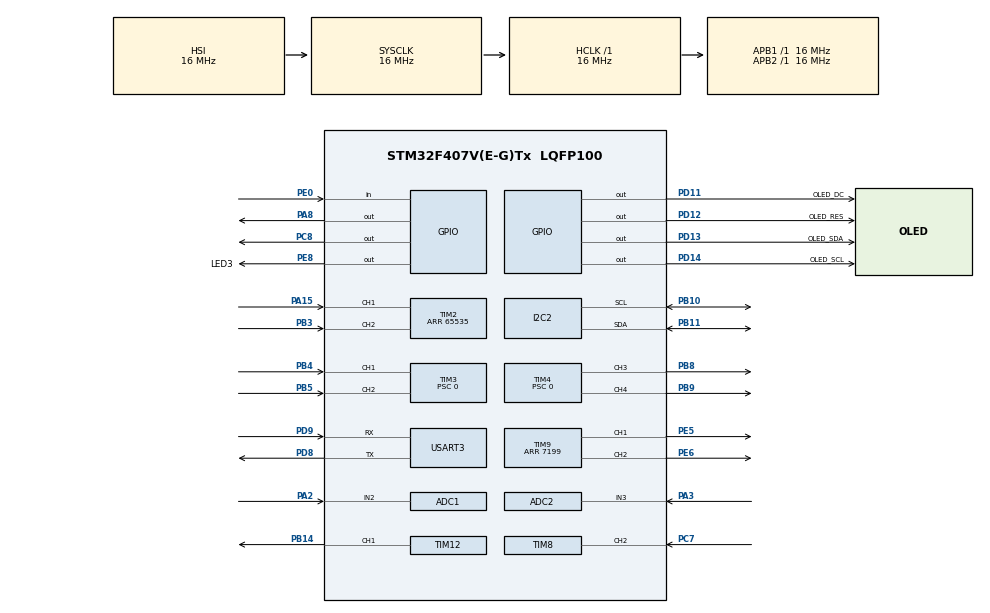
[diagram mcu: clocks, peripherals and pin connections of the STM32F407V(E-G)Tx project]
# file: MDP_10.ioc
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ADC1.Channel-1\#ChannelRegularConversion=ADC_CHANNEL_2
ADC1.NbrOfConversionFlag=1
ADC1.Rank-1\#ChannelRegularConversion=1
ADC1.SamplingTime-1\#ChannelRegularConversion=ADC_SAMPLETIME_3CYCLES
ADC1.master=1
ADC2.Channel-0\#ChannelRegularConversion=ADC_CHANNEL_3
ADC2.NbrOfConversionFlag=1
ADC2.Rank-0\#ChannelRegularConversion=1
ADC2.SamplingTime-0\#ChannelRegularConversion=ADC_SAMPLETIME_3CYCLES
FREERTOS.Tasks01=defaultTask,8,128,StartDefaultTask,Default,NULL,Dynamic,NULL,NULL;ShowTask,8,128,show,Default,NULL,Dynamic,NULL,NULL;MotorTask,8,128,motors,Default,NULL,Dynamic,NULL,NULL;EncoderTask,8,256,encoder,Default,NULL,Dynamic,NULL,NULL;ServoTask,8,128,servo,Default,NULL,Dynamic,NULL,NULL;EncoderBTask,8,256,encoder_B,Default,NULL,Dynamic,NULL,NULL;UltrasonicSenso,8,128,ultra_sensor,Default,NULL,Dynamic,NULL,NULL;sensorTask,8,512,sensor_reading,Default,NULL,Dynamic,NULL,NULL;IRDistTask,8,512,ir_dist,Default,NULL,Dynamic,NULL,NULL;transmitTask,8,512,transmit,Default,NULL,Dynamic,NULL,NULL;encoderDiffTask,8,128,encoder_diff,Default,NULL,Dynamic,NULL,NULL;turningTask,8,128,turning_task,Default,NULL,Dynamic,NULL,NULL
FREERTOS.configUSE_NEWLIB_REENTRANT=1
I2C2.I2C_Mode=I2C_Fast
Mcu.Family=STM32F4
Mcu.Name=STM32F407V(E-G)Tx
Mcu.Package=LQFP100
NVIC.PriorityGroup=NVIC_PRIORITYGROUP_4
NVIC.TIM6_DAC_IRQn=true\:15\:0\:false\:false\:true\:false\:false\:true\:true
NVIC.TIM8_CC_IRQn=true\:5\:0\:false\:false\:true\:true\:true\:true\:true
NVIC.TimeBase=TIM6_DAC_IRQn
NVIC.TimeBaseIP=TIM6
NVIC.USART3_IRQn=true\:5\:0\:false\:false\:true\:true\:true\:true\:true
PA15.Signal=S_TIM2_CH1_ETR
PA2.Signal=ADCx_IN2
PA3.Signal=ADCx_IN3
PA8.Signal=GPIO_Output
PB10.Mode=I2C
PB10.Signal=I2C2_SCL
PB11.Mode=I2C
PB11.Signal=I2C2_SDA
PB14.Signal=S_TIM12_CH1
PB3.Signal=S_TIM2_CH2
PB4.Signal=S_TIM3_CH1
PB5.Signal=S_TIM3_CH2
PB8.Signal=S_TIM4_CH3
PB9.Signal=S_TIM4_CH4
PC7.Signal=S_TIM8_CH2
PC8.Signal=GPIO_Output
PD11.GPIO_Label=OLED_DC
PD11.Signal=GPIO_Output
PD12.GPIO_Label=OLED_RES
PD12.Signal=GPIO_Output
PD13.GPIO_Label=OLED_SDA
PD13.Signal=GPIO_Output
PD14.GPIO_Label=OLED_SCL
PD14.Signal=GPIO_Output
PD8.Mode=Asynchronous
PD8.Signal=USART3_TX
PD9.Mode=Asynchronous
PD9.Signal=USART3_RX
PE0.Signal=GPIO_Input
PE5.Signal=S_TIM9_CH1
PE6.Signal=S_TIM9_CH2
PE8.GPIO_Label=LED3
PE8.Signal=GPIO_Output
ProjectManager.HeapSize=0x200
ProjectManager.StackSize=0x400
ProjectManager.TargetToolchain=STM32CubeIDE
RCC.AHBFreq_Value=16000000
RCC.APB1Freq_Value=16000000
RCC.APB2Freq_Value=16000000
RCC.CortexFreq_Value=16000000
RCC.HSE_VALUE=25000000
RCC.HSI_VALUE=16000000
RCC.LSE_VALUE=32768
RCC.SYSCLKFreq_VALUE=16000000
RCC.VCOOutputFreq_Value=192000000
SH.ADCx_IN2.0=ADC1_IN2,IN2
SH.ADCx_IN3.0=ADC2_IN3,IN3
SH.S_TIM12_CH1.0=TIM12_CH1,PWM Generation1 CH1
SH.S_TIM2_CH1_ETR.0=TIM2_CH1,Encoder_Interface
SH.S_TIM2_CH2.0=TIM2_CH2,Encoder_Interface
SH.S_TIM3_CH1.0=TIM3_CH1,Encoder_Interface
SH.S_TIM3_CH2.0=TIM3_CH2,Encoder_Interface
SH.S_TIM4_CH3.0=TIM4_CH3,PWM Generation3 CH3
SH.S_TIM4_CH4.0=TIM4_CH4,PWM Generation4 CH4
SH.S_TIM8_CH2.0=TIM8_CH2,Input_Capture2_from_TI2
SH.S_TIM9_CH1.0=TIM9_CH1,PWM Generation1 CH1
SH.S_TIM9_CH2.0=TIM9_CH2,PWM Generation2 CH2
TIM1.Period=7199
TIM12.AutoReloadPreload=TIM_AUTORELOAD_PRELOAD_ENABLE
TIM12.Channel-PWM\ Generation1\ CH1=TIM_CHANNEL_1
TIM12.Period=1000
TIM12.Prescaler=320
TIM14.Prescaler=16-1
TIM2.EncoderMode=TIM_ENCODERMODE_TI12
TIM2.IC1Filter=10
TIM2.IC2Filter=10
TIM2.Period=65535
TIM3.AutoReloadPreload=TIM_AUTORELOAD_PRELOAD_ENABLE
TIM3.EncoderMode=TIM_ENCODERMODE_TI12
TIM3.IC1Filter=10
TIM3.IC2Filter=10
TIM3.Period=65535
TIM3.Prescaler=0
TIM4.Channel-PWM\ Generation3\ CH3=TIM_CHANNEL_3
TIM4.Channel-PWM\ Generation4\ CH4=TIM_CHANNEL_4
TIM4.OCPolarity_3=TIM_OCPOLARITY_LOW
TIM4.OCPolarity_4=TIM_OCPOLARITY_LOW
TIM4.Period=7199
TIM4.Prescaler=0
TIM8.Channel-Input_Capture2_from_TI2=TIM_CHANNEL_2
TIM8.ICPolarity_CH2=TIM_INPUTCHANNELPOLARITY_BOTHEDGE
TIM8.Prescaler=16-1
TIM9.Channel-PWM\ Generation1\ CH1=TIM_CHANNEL_1
TIM9.Channel-PWM\ Generation2\ CH2=TIM_CHANNEL_2
TIM9.OCPolarity_1=TIM_OCPOLARITY_LOW
TIM9.OCPolarity_2=TIM_OCPOLARITY_LOW
TIM9.Period=7199
USART3.VirtualMode=VM_ASYNC
VP_FREERTOS_VS_CMSIS_V2.Mode=CMSIS_V2
VP_SYS_VS_tim6.Mode=TIM6
VP_TIM12_VS_ClockSourceINT.Mode=Internal
VP_TIM14_VS_ClockSourceINT.Mode=Enable_Timer
VP_TIM1_VS_ClockSourceINT.Mode=Internal
VP_TIM4_VS_ClockSourceINT.Mode=Internal
VP_TIM8_VS_ClockSourceINT.Mode=Internal
VP_TIM9_VS_ClockSourceINT.Mode=Internal
board=custom

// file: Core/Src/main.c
/* USER CODE BEGIN Header */
/**
  ******************************************************************************
  * @file           : main.c
  * @brief          : Main program body
  ******************************************************************************
  * @attention
  *
  * Copyright (c) 2025 STMicroelectronics.
  * All rights reserved.
  *
  * This software is licensed under terms that can be found in the LICENSE file
  * in the root directory of this software component.
  * If no LICENSE file comes with this software, it is provided AS-IS.
  *
  ******************************************************************************
  */
/* USER CODE END Header */
#include "main.h"
#include "cmsis_os.h"

/* USER CODE BEGIN Includes */
#include "oled.h"
#include <string.h>
#include <stdio.h>
#include <stdlib.h>
#include "stm32f4xx_hal.h"
/* USER CODE END Includes */

/* USER CODE BEGIN PD */
#define ECHO_Port 	GPIOC
#define ECHO_Pin	GPIO_PIN_7
#define TRIG_Port	GPIOC
#define TRIG_Pin	GPIO_PIN_8
/* USER CODE END PD */

ADC_HandleTypeDef hadc1;
ADC_HandleTypeDef hadc2;

I2C_HandleTypeDef hi2c2;

TIM_HandleTypeDef htim1;
TIM_HandleTypeDef htim2;
TIM_HandleTypeDef htim3;
TIM_HandleTypeDef htim4;
TIM_HandleTypeDef htim8;
TIM_HandleTypeDef htim9;
TIM_HandleTypeDef htim12;
TIM_HandleTypeDef htim14;

UART_HandleTypeDef huart3;

/* Definitions for defaultTask */
osThreadId_t defaultTaskHandle;
const osThreadAttr_t defaultTask_attributes = {
  .name = "defaultTask",
  .stack_size = 128 * 4,
  .priority = (osPriority_t) osPriorityLow,
};
/* Definitions for ShowTask */
osThreadId_t ShowTaskHandle;
const osThreadAttr_t ShowTask_attributes = {
  .name = "ShowTask",
  .stack_size = 128 * 4,
  .priority = (osPriority_t) osPriorityLow,
};
/* Definitions for MotorTask */
osThreadId_t MotorTaskHandle;
const osThreadAttr_t MotorTask_attributes = {
  .name = "MotorTask",
  .stack_size = 128 * 4,
  .priority = (osPriority_t) osPriorityLow,
};
/* Definitions for EncoderTask */
osThreadId_t EncoderTaskHandle;
const osThreadAttr_t EncoderTask_attributes = {
  .name = "EncoderTask",
  .stack_size = 256 * 4,
  .priority = (osPriority_t) osPriorityLow,
};
/* Definitions for EncoderBTask */
osThreadId_t EncoderBTaskHandle;
const osThreadAttr_t EncoderBTask_attributes = {
  .name = "EncoderBTask",
  .stack_size = 256 * 4,
  .priority = (osPriority_t) osPriorityLow,
};
/* Definitions for UltrasonicSenso */
osThreadId_t UltrasonicSensoHandle;
const osThreadAttr_t UltrasonicSenso_attributes = {
  .name = "UltrasonicSenso",
  .stack_size = 128 * 4,
  .priority = (osPriority_t) osPriorityLow,
};
/* Definitions for sensorTask */
osThreadId_t sensorTaskHandle;
const osThreadAttr_t sensorTask_attributes = {
  .name = "sensorTask",
  .stack_size = 512 * 4,
  .priority = (osPriority_t) osPriorityLow,
};
/* Definitions for IRDistTask */
osThreadId_t IRDistTaskHandle;
const osThreadAttr_t IRDistTask_attributes = {
  .name = "IRDistTask",
  .stack_size = 512 * 4,
  .priority = (osPriority_t) osPriorityLow,
};
/* Definitions for transmitTask */
osThreadId_t transmitTaskHandle;
const osThreadAttr_t transmitTask_attributes = {
  .name = "transmitTask",
  .stack_size = 512 * 4,
  .priority = (osPriority_t) osPriorityLow,
};
/* Definitions for encoderDiffTask */
osThreadId_t encoderDiffTaskHandle;
const osThreadAttr_t encoderDiffTask_attributes = {
  .name = "encoderDiffTask",
  .stack_size = 128 * 4,
  .priority = (osPriority_t) osPriorityLow,
};

void SystemClock_Config(void);
static void MX_GPIO_Init(void);
static void MX_TIM4_Init(void);
static void MX_TIM2_Init(void);
static void MX_TIM12_Init(void);
static void MX_TIM3_Init(void);
static void MX_TIM9_Init(void);
static void MX_TIM1_Init(void);
static void MX_TIM8_Init(void);
static void MX_TIM14_Init(void);
static void MX_I2C2_Init(void);
static void MX_ADC1_Init(void);
static void MX_ADC2_Init(void);
static void MX_USART3_UART_Init(void);
void StartDefaultTask(void *argument);
void show(void *argument);
void motors(void *argument);
void encoder(void *argument);
void encoder_B(void *argument);
void ultra_sensor(void *argument);
void sensor_reading(void *argument);
void ir_dist(void *argument);
void transmit(void *argument);
void encoder_diff(void *argument);

/* USER CODE BEGIN PFP */
void MotorDrive_enable(void){
	HAL_TIM_PWM_Start(&htim4, TIM_CHANNEL_3);
	HAL_TIM_PWM_Start(&htim4, TIM_CHANNEL_4);
	HAL_TIM_PWM_Start(&htim9, TIM_CHANNEL_1);
	HAL_TIM_PWM_Start(&htim9, TIM_CHANNEL_2);
}

void MotorStop_both(void){
	__HAL_TIM_SetCompare(&htim9, TIM_CHANNEL_1, 0);
	__HAL_TIM_SetCompare(&htim9, TIM_CHANNEL_2, 0);
	__HAL_TIM_SetCompare(&htim4, TIM_CHANNEL_3, 0);
	__HAL_TIM_SetCompare(&htim4, TIM_CHANNEL_4, 0);
}

/* USER CODE END PFP */

/* USER CODE BEGIN 0 */

//-------- IR sensor ----------
float ir_dist_left = 0;
float ir_dist_right = 0;
float ir_dist_left_prev = 0.0f;
float ir_dist_right_prev = 0.0f;
float ir_dist_left_lpf = 0.0f;
float ir_dist_right_lpf = 0.0f;
uint16_t ir_raw_left = 0;
uint16_t ir_raw_right = 0;
int ir_dist_right_int = 0;
int ir_dist_left_int = 0;
//----------------------------

//------ Gyrometer ------
int16_t gyro_z_raw = 0;
float gyro_z_dps = 0.0f;
int gyro_z_dps_int = 0;
float gyro_z_dps_prev = 0.0f;
float angle_direction = 0.0f;
int angle_direction_int = 0;
float prev_angle_direction = 0.0f;

float angle_direction_hpf = 0.0f;
float angle_direction_hpf_prev = 0.0f;
int angle_direction_hpf_int = 0;
//-----------------------

//--- Ultrasonic Sensor ---
int us_echo = 0;
float us_dist = 0.0f;
int tc1 = 0;
int tc2 = 0;
float us_dist_prev = 0.0f;
float us_dist_lpf = 0.0f;
int us_dist_int = 0;
//--------------------------

//------- Motor ------------
#define RPM_OFFSET 5.0f //FORWARD
#define RPM_BACK_OFFSET 2.0f //BACKWARD
int motor_left_encoder = 0;
int motor_right_encoder = 0;
int prev_left_encoder = 0;
int prev_right_encoder = 0;

float motor_left_encoder_lpf = 0;
float motor_right_encoder_lpf = 0;
float motor_left_encoder_lpf_prev = 0;
float motor_right_encoder_lpf_prev = 0;

uint32_t total_left_encoder = 0;
uint32_t total_right_encoder = 0;
int distance_travelled_int = 0;
float distance_travelled = 0.0f;
float total_revolution = 0.0f;
int total_revolution_int = 0;
int total_encoder = 0;

float motor_left_rpm = 0.0f;
float motor_right_rpm = 0.0f;
int motor_left_rpm_int = 0;
int motor_right_rpm_int = 0;

float motor_left_rpm_lpf = 0.0f;
float motor_right_rpm_lpf = 0.0f;
int motor_left_rpm_lpf_int = 0;
int motor_right_rpm_lpf_int = 0;

int encoder_difference = 0;

int motor_stop = 0;
//--------------------------------

//-------- UART ------------
uint8_t aRxBuffer[5];
uint8_t uart_byte;
uint8_t uart_rx_buffer[64];
uint8_t uart_index = 0;
char last_oled_msg[32] = "";
char instruction[32] = "";

int have_instruction = 0;
int instruction_type = 0;
char buffer[64];

char i_flag;
char i_speed_str[2], i_angle_str[2], i_value_str[2];
float i_speed, i_angle, i_value;
char temp[10];
int temp_i;
int emergency_stop = 0;
//--------------------------

//------------ PID Controller ----------
/* OLD
#define OUTPUT_MIN_MOTOR -2500
#define OUTPUT_MAX_MOTOR 2500
#define OUTPUT_MAX_PWM_MOTOR 2500
#define OUTPUT_MIN_PWM_MOTOR 0
#define INTEGRAL_MAX_MOTOR 200

#define OUTPUT_MIN_ANGLE -2500
#define OUTPUT_MAX_ANGLE 2500
#define OUTPUT_MAX_PWM_ANGLE 2500
#define OUTPUT_MIN_PWM_ANGLE0
#define INTEGRAL_MAX_ANGLE 200
*/

/* JONAH */
#define OUTPUT_MIN_MOTOR      -7200
#define OUTPUT_MAX_MOTOR       7200
#define OUTPUT_MAX_PWM_MOTOR   7200
#define OUTPUT_MIN_PWM_MOTOR   0
#define INTEGRAL_MAX_MOTOR     500

#define OUTPUT_MIN_ANGLE      -7200
#define OUTPUT_MAX_ANGLE       7200
#define OUTPUT_MAX_PWM_ANGLE   7200
#define OUTPUT_MIN_PWM_ANGLE   0
#define INTEGRAL_MAX_ANGLE     500

typedef struct {
	float Kp;
	float Ki;
	float Kd;
	int prevError;
	int integral;
	int pid_change;
	int pwm_output;
} PID_Controller;

void setPID(PID_Controller *pid, float Kp, float Ki, float Kd, int pwm_output){
	pid->Kp = Kp;
	pid->Ki = Ki;
	pid->Kd = Kd;
	pid->pwm_output = pwm_output;
}
PID_Controller pid_left, pid_right, pid_angle;

//--------------------------------------

//---------------- Miscellaneous --------------------
#define SERVO_LEFT 53
#define SERVO_MIDDLE 76
#define SERVO_RIGHT 115
#define LEFT 1
#define RIGHT 0
#define FORWARD 1
#define REVERSE 0
int servo_prev = SERVO_LEFT;
int servo_curr = 0;

int error_left_encoder = 0, error_right_encoder = 0;
float error_left_rpm = 0.0f, error_right_rpm = 0.0f;
float deadband_left = 250.0f, deadband_right = 250.0f;
int pwm_left = 0, pwm_right = 0;
float error_angle = 0.0f;
int error_angle_int = 0;
//----------------------------------------------------

/* USER CODE END 0 */

int main(void)
{

  /* MCU Configuration--------------------------------------------------------*/

  /* Reset of all peripherals, Initializes the Flash interface and the Systick. */
  HAL_Init();

  /* Configure the system clock */
  SystemClock_Config();

  /* Initialize all configured peripherals */
  MX_GPIO_Init();
  MX_TIM4_Init();
  MX_TIM2_Init();
  MX_TIM12_Init();
  MX_TIM3_Init();
  MX_TIM9_Init();
  MX_TIM1_Init();
  MX_TIM8_Init();
  MX_TIM14_Init();
  MX_I2C2_Init();
  MX_ADC1_Init();
  MX_ADC2_Init();
  MX_USART3_UART_Init();
  /* USER CODE BEGIN 2 */
  OLED_Init();
  HAL_UART_Receive_IT(&huart3, &uart_byte, 1);

  /* USER CODE END 2 */

  /* Init scheduler */
  osKernelInitialize();

  /* Create the thread(s) */
  /* creation of defaultTask */
  defaultTaskHandle = osThreadNew(StartDefaultTask, NULL, &defaultTask_attributes);

  /* creation of ShowTask */
  ShowTaskHandle = osThreadNew(show, NULL, &ShowTask_attributes);

  /* creation of MotorTask */
  MotorTaskHandle = osThreadNew(motors, NULL, &MotorTask_attributes);

  /* creation of EncoderTask */
  EncoderTaskHandle = osThreadNew(encoder, NULL, &EncoderTask_attributes);

  /* creation of EncoderBTask */
  EncoderBTaskHandle = osThreadNew(encoder_B, NULL, &EncoderBTask_attributes);

  /* creation of UltrasonicSenso */
  UltrasonicSensoHandle = osThreadNew(ultra_sensor, NULL, &UltrasonicSenso_attributes);

  /* creation of sensorTask */
  sensorTaskHandle = osThreadNew(sensor_reading, NULL, &sensorTask_attributes);

  /* creation of IRDistTask */
  IRDistTaskHandle = osThreadNew(ir_dist, NULL, &IRDistTask_attributes);

  /* creation of transmitTask */
  transmitTaskHandle = osThreadNew(transmit, NULL, &transmitTask_attributes);

  /* creation of encoderDiffTask */
  encoderDiffTaskHandle = osThreadNew(encoder_diff, NULL, &encoderDiffTask_attributes);

  /* Start scheduler */
  osKernelStart();

  /* We should never get here as control is now taken by the scheduler */

  /* Infinite loop */
  while (1)
  {

  }
}

void SystemClock_Config(void)
{
  RCC_OscInitTypeDef RCC_OscInitStruct = {0};
  RCC_ClkInitTypeDef RCC_ClkInitStruct = {0};

  /** Configure the main internal regulator output voltage
  */
  __HAL_RCC_PWR_CLK_ENABLE();
  __HAL_PWR_VOLTAGESCALING_CONFIG(PWR_REGULATOR_VOLTAGE_SCALE1);

  /** Initializes the RCC Oscillators according to the specified parameters
  * in the RCC_OscInitTypeDef structure.
  */
  RCC_OscInitStruct.OscillatorType = RCC_OSCILLATORTYPE_HSI;
  RCC_OscInitStruct.HSIState = RCC_HSI_ON;
  RCC_OscInitStruct.HSICalibrationValue = RCC_HSICALIBRATION_DEFAULT;
  RCC_OscInitStruct.PLL.PLLState = RCC_PLL_NONE;
  if (HAL_RCC_OscConfig(&RCC_OscInitStruct) != HAL_OK)
  {
    Error_Handler();
  }

  /** Initializes the CPU, AHB and APB buses clocks
  */
  RCC_ClkInitStruct.ClockType = RCC_CLOCKTYPE_HCLK|RCC_CLOCKTYPE_SYSCLK
                              |RCC_CLOCKTYPE_PCLK1|RCC_CLOCKTYPE_PCLK2;
  RCC_ClkInitStruct.SYSCLKSource = RCC_SYSCLKSOURCE_HSI;
  RCC_ClkInitStruct.AHBCLKDivider = RCC_SYSCLK_DIV1;
  RCC_ClkInitStruct.APB1CLKDivider = RCC_HCLK_DIV1;
  RCC_ClkInitStruct.APB2CLKDivider = RCC_HCLK_DIV1;

  if (HAL_RCC_ClockConfig(&RCC_ClkInitStruct, FLASH_LATENCY_0) != HAL_OK)
  {
    Error_Handler();
  }
}

static void MX_ADC1_Init(void)
{

  ADC_ChannelConfTypeDef sConfig = {0};

  /** Configure the global features of the ADC (Clock, Resolution, Data Alignment and number of conversion)
  */
  hadc1.Instance = ADC1;
  hadc1.Init.ClockPrescaler = ADC_CLOCK_SYNC_PCLK_DIV2;
  hadc1.Init.Resolution = ADC_RESOLUTION_12B;
  hadc1.Init.ScanConvMode = DISABLE;
  hadc1.Init.ContinuousConvMode = DISABLE;
  hadc1.Init.DiscontinuousConvMode = DISABLE;
  hadc1.Init.ExternalTrigConvEdge = ADC_EXTERNALTRIGCONVEDGE_NONE;
  hadc1.Init.ExternalTrigConv = ADC_SOFTWARE_START;
  hadc1.Init.DataAlign = ADC_DATAALIGN_RIGHT;
  hadc1.Init.NbrOfConversion = 1;
  hadc1.Init.DMAContinuousRequests = DISABLE;
  hadc1.Init.EOCSelection = ADC_EOC_SINGLE_CONV;
  if (HAL_ADC_Init(&hadc1) != HAL_OK)
  {
    Error_Handler();
  }

  /** Configure for the selected ADC regular channel its corresponding rank in the sequencer and its sample time.
  */
  sConfig.Channel = ADC_CHANNEL_2;
  sConfig.Rank = 1;
  sConfig.SamplingTime = ADC_SAMPLETIME_3CYCLES;
  if (HAL_ADC_ConfigChannel(&hadc1, &sConfig) != HAL_OK)
  {
    Error_Handler();
  }

}

static void MX_ADC2_Init(void)
{

  ADC_ChannelConfTypeDef sConfig = {0};

  /** Configure the global features of the ADC (Clock, Resolution, Data Alignment and number of conversion)
  */
  hadc2.Instance = ADC2;
  hadc2.Init.ClockPrescaler = ADC_CLOCK_SYNC_PCLK_DIV2;
  hadc2.Init.Resolution = ADC_RESOLUTION_12B;
  hadc2.Init.ScanConvMode = DISABLE;
  hadc2.Init.ContinuousConvMode = DISABLE;
  hadc2.Init.DiscontinuousConvMode = DISABLE;
  hadc2.Init.ExternalTrigConvEdge = ADC_EXTERNALTRIGCONVEDGE_NONE;
  hadc2.Init.ExternalTrigConv = ADC_SOFTWARE_START;
  hadc2.Init.DataAlign = ADC_DATAALIGN_RIGHT;
  hadc2.Init.NbrOfConversion = 1;
  hadc2.Init.DMAContinuousRequests = DISABLE;
  hadc2.Init.EOCSelection = ADC_EOC_SINGLE_CONV;
  if (HAL_ADC_Init(&hadc2) != HAL_OK)
  {
    Error_Handler();
  }

  /** Configure for the selected ADC regular channel its corresponding rank in the sequencer and its sample time.
  */
  sConfig.Channel = ADC_CHANNEL_3;
  sConfig.Rank = 1;
  sConfig.SamplingTime = ADC_SAMPLETIME_3CYCLES;
  if (HAL_ADC_ConfigChannel(&hadc2, &sConfig) != HAL_OK)
  {
    Error_Handler();
  }

}

static void MX_I2C2_Init(void)
{

  hi2c2.Instance = I2C2;
  hi2c2.Init.ClockSpeed = 400000;
  hi2c2.Init.DutyCycle = I2C_DUTYCYCLE_2;
  hi2c2.Init.OwnAddress1 = 0;
  hi2c2.Init.AddressingMode = I2C_ADDRESSINGMODE_7BIT;
  hi2c2.Init.DualAddressMode = I2C_DUALADDRESS_DISABLE;
  hi2c2.Init.OwnAddress2 = 0;
  hi2c2.Init.GeneralCallMode = I2C_GENERALCALL_DISABLE;
  hi2c2.Init.NoStretchMode = I2C_NOSTRETCH_DISABLE;
  if (HAL_I2C_Init(&hi2c2) != HAL_OK)
  {
    Error_Handler();
  }

}

static void MX_TIM1_Init(void)
{

  TIM_ClockConfigTypeDef sClockSourceConfig = {0};
  TIM_MasterConfigTypeDef sMasterConfig = {0};

  htim1.Instance = TIM1;
  htim1.Init.Prescaler = 0;
  htim1.Init.CounterMode = TIM_COUNTERMODE_UP;
  htim1.Init.Period = 7199;
  htim1.Init.ClockDivision = TIM_CLOCKDIVISION_DIV1;
  htim1.Init.RepetitionCounter = 0;
  htim1.Init.AutoReloadPreload = TIM_AUTORELOAD_PRELOAD_DISABLE;
  if (HAL_TIM_Base_Init(&htim1) != HAL_OK)
  {
    Error_Handler();
  }
  sClockSourceConfig.ClockSource = TIM_CLOCKSOURCE_INTERNAL;
  if (HAL_TIM_ConfigClockSource(&htim1, &sClockSourceConfig) != HAL_OK)
  {
    Error_Handler();
  }
  sMasterConfig.MasterOutputTrigger = TIM_TRGO_RESET;
  sMasterConfig.MasterSlaveMode = TIM_MASTERSLAVEMODE_DISABLE;
  if (HAL_TIMEx_MasterConfigSynchronization(&htim1, &sMasterConfig) != HAL_OK)
  {
    Error_Handler();
  }

}

static void MX_TIM2_Init(void)
{

  TIM_Encoder_InitTypeDef sConfig = {0};
  TIM_MasterConfigTypeDef sMasterConfig = {0};

  htim2.Instance = TIM2;
  htim2.Init.Prescaler = 0;
  htim2.Init.CounterMode = TIM_COUNTERMODE_UP;
  htim2.Init.Period = 65535;
  htim2.Init.ClockDivision = TIM_CLOCKDIVISION_DIV1;
  htim2.Init.AutoReloadPreload = TIM_AUTORELOAD_PRELOAD_DISABLE;
  sConfig.EncoderMode = TIM_ENCODERMODE_TI12;
  sConfig.IC1Polarity = TIM_ICPOLARITY_RISING;
  sConfig.IC1Selection = TIM_ICSELECTION_DIRECTTI;
  sConfig.IC1Prescaler = TIM_ICPSC_DIV1;
  sConfig.IC1Filter = 10;
  sConfig.IC2Polarity = TIM_ICPOLARITY_RISING;
  sConfig.IC2Selection = TIM_ICSELECTION_DIRECTTI;
  sConfig.IC2Prescaler = TIM_ICPSC_DIV1;
  sConfig.IC2Filter = 10;
  if (HAL_TIM_Encoder_Init(&htim2, &sConfig) != HAL_OK)
  {
    Error_Handler();
  }
  sMasterConfig.MasterOutputTrigger = TIM_TRGO_RESET;
  sMasterConfig.MasterSlaveMode = TIM_MASTERSLAVEMODE_DISABLE;
  if (HAL_TIMEx_MasterConfigSynchronization(&htim2, &sMasterConfig) != HAL_OK)
  {
    Error_Handler();
  }

}

static void MX_TIM3_Init(void)
{

  TIM_Encoder_InitTypeDef sConfig = {0};
  TIM_MasterConfigTypeDef sMasterConfig = {0};

  htim3.Instance = TIM3;
  htim3.Init.Prescaler = 0;
  htim3.Init.CounterMode = TIM_COUNTERMODE_UP;
  htim3.Init.Period = 65535;
  htim3.Init.ClockDivision = TIM_CLOCKDIVISION_DIV1;
  htim3.Init.AutoReloadPreload = TIM_AUTORELOAD_PRELOAD_ENABLE;
  sConfig.EncoderMode = TIM_ENCODERMODE_TI12;
  sConfig.IC1Polarity = TIM_ICPOLARITY_RISING;
  sConfig.IC1Selection = TIM_ICSELECTION_DIRECTTI;
  sConfig.IC1Prescaler = TIM_ICPSC_DIV1;
  sConfig.IC1Filter = 10;
  sConfig.IC2Polarity = TIM_ICPOLARITY_RISING;
  sConfig.IC2Selection = TIM_ICSELECTION_DIRECTTI;
  sConfig.IC2Prescaler = TIM_ICPSC_DIV1;
  sConfig.IC2Filter = 10;
  if (HAL_TIM_Encoder_Init(&htim3, &sConfig) != HAL_OK)
  {
    Error_Handler();
  }
  sMasterConfig.MasterOutputTrigger = TIM_TRGO_RESET;
  sMasterConfig.MasterSlaveMode = TIM_MASTERSLAVEMODE_DISABLE;
  if (HAL_TIMEx_MasterConfigSynchronization(&htim3, &sMasterConfig) != HAL_OK)
  {
    Error_Handler();
  }

}

static void MX_TIM4_Init(void)
{

  TIM_ClockConfigTypeDef sClockSourceConfig = {0};
  TIM_MasterConfigTypeDef sMasterConfig = {0};
  TIM_OC_InitTypeDef sConfigOC = {0};

  htim4.Instance = TIM4;
  htim4.Init.Prescaler = 0;
  htim4.Init.CounterMode = TIM_COUNTERMODE_UP;
  htim4.Init.Period = 7199;
  htim4.Init.ClockDivision = TIM_CLOCKDIVISION_DIV1;
  htim4.Init.AutoReloadPreload = TIM_AUTORELOAD_PRELOAD_DISABLE;
  if (HAL_TIM_Base_Init(&htim4) != HAL_OK)
  {
    Error_Handler();
  }
  sClockSourceConfig.ClockSource = TIM_CLOCKSOURCE_INTERNAL;
  if (HAL_TIM_ConfigClockSource(&htim4, &sClockSourceConfig) != HAL_OK)
  {
    Error_Handler();
  }
  if (HAL_TIM_PWM_Init(&htim4) != HAL_OK)
  {
    Error_Handler();
  }
  sMasterConfig.MasterOutputTrigger = TIM_TRGO_RESET;
  sMasterConfig.MasterSlaveMode = TIM_MASTERSLAVEMODE_DISABLE;
  if (HAL_TIMEx_MasterConfigSynchronization(&htim4, &sMasterConfig) != HAL_OK)
  {
    Error_Handler();
  }
  sConfigOC.OCMode = TIM_OCMODE_PWM1;
  sConfigOC.Pulse = 0;
  sConfigOC.OCPolarity = TIM_OCPOLARITY_LOW;
  sConfigOC.OCFastMode = TIM_OCFAST_DISABLE;
  if (HAL_TIM_PWM_ConfigChannel(&htim4, &sConfigOC, TIM_CHANNEL_3) != HAL_OK)
  {
    Error_Handler();
  }
  if (HAL_TIM_PWM_ConfigChannel(&htim4, &sConfigOC, TIM_CHANNEL_4) != HAL_OK)
  {
    Error_Handler();
  }
  HAL_TIM_MspPostInit(&htim4);

}

static void MX_TIM8_Init(void)
{

  TIM_ClockConfigTypeDef sClockSourceConfig = {0};
  TIM_MasterConfigTypeDef sMasterConfig = {0};
  TIM_IC_InitTypeDef sConfigIC = {0};

  htim8.Instance = TIM8;
  htim8.Init.Prescaler = 16-1;
  htim8.Init.CounterMode = TIM_COUNTERMODE_UP;
  htim8.Init.Period = 65535;
  htim8.Init.ClockDivision = TIM_CLOCKDIVISION_DIV1;
  htim8.Init.RepetitionCounter = 0;
  htim8.Init.AutoReloadPreload = TIM_AUTORELOAD_PRELOAD_DISABLE;
  if (HAL_TIM_Base_Init(&htim8) != HAL_OK)
  {
    Error_Handler();
  }
  sClockSourceConfig.ClockSource = TIM_CLOCKSOURCE_INTERNAL;
  if (HAL_TIM_ConfigClockSource(&htim8, &sClockSourceConfig) != HAL_OK)
  {
    Error_Handler();
  }
  if (HAL_TIM_IC_Init(&htim8) != HAL_OK)
  {
    Error_Handler();
  }
  sMasterConfig.MasterOutputTrigger = TIM_TRGO_RESET;
  sMasterConfig.MasterSlaveMode = TIM_MASTERSLAVEMODE_DISABLE;
  if (HAL_TIMEx_MasterConfigSynchronization(&htim8, &sMasterConfig) != HAL_OK)
  {
    Error_Handler();
  }
  sConfigIC.ICPolarity = TIM_INPUTCHANNELPOLARITY_BOTHEDGE;
  sConfigIC.ICSelection = TIM_ICSELECTION_DIRECTTI;
  sConfigIC.ICPrescaler = TIM_ICPSC_DIV1;
  sConfigIC.ICFilter = 0;
  if (HAL_TIM_IC_ConfigChannel(&htim8, &sConfigIC, TIM_CHANNEL_2) != HAL_OK)
  {
    Error_Handler();
  }

}

static void MX_TIM9_Init(void)
{

  TIM_ClockConfigTypeDef sClockSourceConfig = {0};
  TIM_OC_InitTypeDef sConfigOC = {0};

  htim9.Instance = TIM9;
  htim9.Init.Prescaler = 0;
  htim9.Init.CounterMode = TIM_COUNTERMODE_UP;
  htim9.Init.Period = 7199;
  htim9.Init.ClockDivision = TIM_CLOCKDIVISION_DIV1;
  htim9.Init.AutoReloadPreload = TIM_AUTORELOAD_PRELOAD_DISABLE;
  if (HAL_TIM_Base_Init(&htim9) != HAL_OK)
  {
    Error_Handler();
  }
  sClockSourceConfig.ClockSource = TIM_CLOCKSOURCE_INTERNAL;
  if (HAL_TIM_ConfigClockSource(&htim9, &sClockSourceConfig) != HAL_OK)
  {
    Error_Handler();
  }
  if (HAL_TIM_PWM_Init(&htim9) != HAL_OK)
  {
    Error_Handler();
  }
  sConfigOC.OCMode = TIM_OCMODE_PWM1;
  sConfigOC.Pulse = 0;
  sConfigOC.OCPolarity = TIM_OCPOLARITY_LOW;
  sConfigOC.OCFastMode = TIM_OCFAST_DISABLE;
  if (HAL_TIM_PWM_ConfigChannel(&htim9, &sConfigOC, TIM_CHANNEL_1) != HAL_OK)
  {
    Error_Handler();
  }
  if (HAL_TIM_PWM_ConfigChannel(&htim9, &sConfigOC, TIM_CHANNEL_2) != HAL_OK)
  {
    Error_Handler();
  }
  HAL_TIM_MspPostInit(&htim9);

}

static void MX_TIM12_Init(void)
{

  TIM_ClockConfigTypeDef sClockSourceConfig = {0};
  TIM_OC_InitTypeDef sConfigOC = {0};

  htim12.Instance = TIM12;
  htim12.Init.Prescaler = 320;
  htim12.Init.CounterMode = TIM_COUNTERMODE_UP;
  htim12.Init.Period = 1000;
  htim12.Init.ClockDivision = TIM_CLOCKDIVISION_DIV1;
  htim12.Init.AutoReloadPreload = TIM_AUTORELOAD_PRELOAD_ENABLE;
  if (HAL_TIM_Base_Init(&htim12) != HAL_OK)
  {
    Error_Handler();
  }
  sClockSourceConfig.ClockSource = TIM_CLOCKSOURCE_INTERNAL;
  if (HAL_TIM_ConfigClockSource(&htim12, &sClockSourceConfig) != HAL_OK)
  {
    Error_Handler();
  }
  if (HAL_TIM_PWM_Init(&htim12) != HAL_OK)
  {
    Error_Handler();
  }
  sConfigOC.OCMode = TIM_OCMODE_PWM1;
  sConfigOC.Pulse = 0;
  sConfigOC.OCPolarity = TIM_OCPOLARITY_HIGH;
  sConfigOC.OCFastMode = TIM_OCFAST_DISABLE;
  if (HAL_TIM_PWM_ConfigChannel(&htim12, &sConfigOC, TIM_CHANNEL_1) != HAL_OK)
  {
    Error_Handler();
  }
  HAL_TIM_MspPostInit(&htim12);

}

static void MX_TIM14_Init(void)
{

  htim14.Instance = TIM14;
  htim14.Init.Prescaler = 16-1;
  htim14.Init.CounterMode = TIM_COUNTERMODE_UP;
  htim14.Init.Period = 65535;
  htim14.Init.ClockDivision = TIM_CLOCKDIVISION_DIV1;
  htim14.Init.AutoReloadPreload = TIM_AUTORELOAD_PRELOAD_DISABLE;
  if (HAL_TIM_Base_Init(&htim14) != HAL_OK)
  {
    Error_Handler();
  }

}

static void MX_USART3_UART_Init(void)
{

  huart3.Instance = USART3;
  huart3.Init.BaudRate = 115200;
  huart3.Init.WordLength = UART_WORDLENGTH_8B;
  huart3.Init.StopBits = UART_STOPBITS_1;
  huart3.Init.Parity = UART_PARITY_NONE;
  huart3.Init.Mode = UART_MODE_TX_RX;
  huart3.Init.HwFlowCtl = UART_HWCONTROL_NONE;
  huart3.Init.OverSampling = UART_OVERSAMPLING_16;
  if (HAL_UART_Init(&huart3) != HAL_OK)
  {
    Error_Handler();
  }

}

static void MX_GPIO_Init(void)
{
  GPIO_InitTypeDef GPIO_InitStruct = {0};

  /* GPIO Ports Clock Enable */
  __HAL_RCC_GPIOE_CLK_ENABLE();
  __HAL_RCC_GPIOA_CLK_ENABLE();
  __HAL_RCC_GPIOB_CLK_ENABLE();
  __HAL_RCC_GPIOD_CLK_ENABLE();
  __HAL_RCC_GPIOC_CLK_ENABLE();

  /*Configure GPIO pin Output Level */
  HAL_GPIO_WritePin(LED3_GPIO_Port, LED3_Pin, GPIO_PIN_RESET);

  /*Configure GPIO pin Output Level */
  HAL_GPIO_WritePin(GPIOD, OLED_DC_Pin|OLED_RES_Pin|OLED_SDA_Pin|OLED_SCL_Pin, GPIO_PIN_RESET);

  /*Configure GPIO pin Output Level */
  HAL_GPIO_WritePin(GPIOC, GPIO_PIN_8, GPIO_PIN_RESET);

  /*Configure GPIO pin Output Level */
  HAL_GPIO_WritePin(GPIOA, GPIO_PIN_8, GPIO_PIN_RESET);

  /*Configure GPIO pin : LED3_Pin */
  GPIO_InitStruct.Pin = LED3_Pin;
  GPIO_InitStruct.Mode = GPIO_MODE_OUTPUT_PP;
  GPIO_InitStruct.Pull = GPIO_NOPULL;
  GPIO_InitStruct.Speed = GPIO_SPEED_FREQ_LOW;
  HAL_GPIO_Init(LED3_GPIO_Port, &GPIO_InitStruct);

  /*Configure GPIO pins : OLED_DC_Pin OLED_RES_Pin OLED_SDA_Pin OLED_SCL_Pin */
  GPIO_InitStruct.Pin = OLED_DC_Pin|OLED_RES_Pin|OLED_SDA_Pin|OLED_SCL_Pin;
  GPIO_InitStruct.Mode = GPIO_MODE_OUTPUT_PP;
  GPIO_InitStruct.Pull = GPIO_NOPULL;
  GPIO_InitStruct.Speed = GPIO_SPEED_FREQ_LOW;
  HAL_GPIO_Init(GPIOD, &GPIO_InitStruct);

  /*Configure GPIO pin : PC8 */
  GPIO_InitStruct.Pin = GPIO_PIN_8;
  GPIO_InitStruct.Mode = GPIO_MODE_OUTPUT_PP;
  GPIO_InitStruct.Pull = GPIO_NOPULL;
  GPIO_InitStruct.Speed = GPIO_SPEED_FREQ_LOW;
  HAL_GPIO_Init(GPIOC, &GPIO_InitStruct);

  /*Configure GPIO pin : PA8 */
  GPIO_InitStruct.Pin = GPIO_PIN_8;
  GPIO_InitStruct.Mode = GPIO_MODE_OUTPUT_PP;
  GPIO_InitStruct.Pull = GPIO_NOPULL;
  GPIO_InitStruct.Speed = GPIO_SPEED_FREQ_LOW;
  HAL_GPIO_Init(GPIOA, &GPIO_InitStruct);

  /*Configure GPIO pin : PE0 */
  GPIO_InitStruct.Pin = GPIO_PIN_0;
  GPIO_InitStruct.Mode = GPIO_MODE_INPUT;
  GPIO_InitStruct.Pull = GPIO_NOPULL;
  HAL_GPIO_Init(GPIOE, &GPIO_InitStruct);

}

/* USER CODE BEGIN 4 */
void delay_us(uint16_t us){
	HAL_TIM_Base_Start(&htim14);
	__HAL_TIM_SET_COUNTER(&htim14, 0);

	while(__HAL_TIM_GET_COUNTER(&htim14) < us);
}

void HAL_TIM_IC_CaptureCallback(TIM_HandleTypeDef *htim){

	if(htim==&htim8){
		if(HAL_GPIO_ReadPin(GPIOC, GPIO_PIN_7) == GPIO_PIN_SET){	//If pin on high, means positive edge
			tc1 = HAL_TIM_ReadCapturedValue(htim, TIM_CHANNEL_2);	//Retrive value and store in tc1
		} else if (HAL_GPIO_ReadPin(GPIOC, GPIO_PIN_7) == GPIO_PIN_RESET){	//If pin on low means negative edge
			tc2 = HAL_TIM_ReadCapturedValue(htim, TIM_CHANNEL_2);	//Retrive val and store in tc2
			if (tc2 > tc1){
				us_echo = tc2-tc1;		//Calculate the differnce = width of pulse
			} else {
				us_echo = (65536-tc1)+tc2;
			}
		}

	}
}

void Motor_direction_both(uint8_t forward) {
	if (forward){// move forward
		__HAL_TIM_SetCompare(&htim9,TIM_CHANNEL_1,0); // set IN1 to maximum PWM (7199) for '1'
		__HAL_TIM_SetCompare(&htim4,TIM_CHANNEL_3,0);
	  }
	else { // reverse
		__HAL_TIM_SetCompare(&htim9,TIM_CHANNEL_2,0); // set IN2 to maximum PWM (7199) for '1'
		__HAL_TIM_SetCompare(&htim4,TIM_CHANNEL_4,0);
	}
}

void display_if_changed(const char* msg)
{
    if (strcmp(last_oled_msg, msg) != 0) {
//        OLED_Clear();
        OLED_ShowString(5, 45, msg); //last row
        strncpy(last_oled_msg, msg, sizeof(last_oled_msg));
    }
}

void HAL_UART_RxCpltCallback(UART_HandleTypeDef *huart){
    if (huart->Instance == USART3){
        switch (uart_byte){
            case '\n':
                uart_rx_buffer[uart_index] = '\0';
                strncpy(instruction, uart_rx_buffer, sizeof(instruction));
                uart_index = 0;

                // -------- CHECK FOR IR COMMAND FIRST (Don't set have_instruction) --------
                if (instruction[0] == 'I') {
                    // IR sensor read: "IL" for left, "IR" for right
                    char ir_response[32];
                    if (instruction[1] == 'L') {
                        sprintf(ir_response, "IR_LEFT:%d\r\n", ir_dist_left_int);
                    } else if (instruction[1] == 'R') {
                        sprintf(ir_response, "IR_RIGHT:%d\r\n", ir_dist_right_int);
                    } else {
                        sprintf(ir_response, "IR_BOTH:%d,%d\r\n", ir_dist_left_int, ir_dist_right_int);
                    }
                    HAL_UART_Transmit(&huart3, (uint8_t*)ir_response, strlen(ir_response), 0xFFFF);
                }
                else if (instruction[0] == 'U') {
                    // Ultrasound: send "US:<cm>"
                    char us_response[24];
                    sprintf(us_response, "US:%d\r\n", us_dist_int);
                    HAL_UART_Transmit(&huart3, (uint8_t*)us_response, strlen(us_response), 0xFFFF);
                }

                // -------- EMERGENCY STOP --------
                else if (instruction[0] == 'X' || strncmp(instruction, "STOP", 4) == 0) {
                    have_instruction = 1;
                    emergency_stop = 1;
                    MotorStop_both();
                    HAL_GPIO_WritePin(GPIOA, GPIO_PIN_8, GPIO_PIN_SET);
                    osDelay(5000);
                    HAL_GPIO_WritePin(GPIOA, GPIO_PIN_8, GPIO_PIN_RESET);
                    HAL_UART_Transmit(&huart3, "STOP_ACK\r\n", 10, 0xFFFF);
                }
                else if (instruction[0] == 'A') {
                    // All sensors in one line: "SENS:<IRL>,<IRR>,<US>"
                    char all_response[48];
                    sprintf(all_response, "SENS:%d,%d,%d\r\n", ir_dist_left_int, ir_dist_right_int, us_dist_int);
                    HAL_UART_Transmit(&huart3, (uint8_t*)all_response, strlen(all_response), 0xFFFF);
                }
                // -------- OTHER COMMANDS (Motor commands) --------
                else {
                    have_instruction = 1;  // Only set for motor commands
                    display_if_changed((char*)instruction);
                    HAL_UART_Transmit(&huart3, "ACK\r\n", 5, 0xFFFF);
                }

                break;

            default:
                if (uart_index < sizeof(uart_rx_buffer) - 1) {
                    uart_rx_buffer[uart_index++] = uart_byte;
                    uart_rx_buffer[uart_index] = '\0';
                }
                break;
        }

        HAL_UART_Receive_IT(&huart3, &uart_byte, 1);
    }
}

void convert_instruction(char *str) {
    // sscanf returns the number of successfully parsed items
    i_flag = str[0];

    i_speed = (str[1] - '0')*10 + (str[2] - '0');

    i_angle = (str[5] - '0')*10 + (str[6] - '0');
    if (str[4] == '-') i_angle *= -1;

    i_value = (str[8]-'0')*100 + (str[9] - '0')*10 + (str[10] - '0') + (str[12]-'0')*0.1;

}

void I2C_Bus_Recovery(void)
{
    GPIO_InitTypeDef GPIO_InitStruct = {0};

    // 1. De-init I2C peripheral
    HAL_I2C_DeInit(&hi2c2);

    // 2. Configure SCL and SDA as GPIO outputs open-drain
    __HAL_RCC_GPIOB_CLK_ENABLE();  // Change port if your I2C2 pins are different

    GPIO_InitStruct.Mode = GPIO_MODE_OUTPUT_OD;
    GPIO_InitStruct.Pull = GPIO_NOPULL;
    GPIO_InitStruct.Speed = GPIO_SPEED_FREQ_LOW;

    GPIO_InitStruct.Pin = GPIO_PIN_10; // SCL (check your board)
    HAL_GPIO_Init(GPIOB, &GPIO_InitStruct);

    GPIO_InitStruct.Pin = GPIO_PIN_11; // SDA (check your board)
    HAL_GPIO_Init(GPIOB, &GPIO_InitStruct);

    // 3. Toggle SCL about 10 times while SDA is high
    for (int i = 0; i < 10; i++)
    {
        HAL_GPIO_WritePin(GPIOB, GPIO_PIN_10, GPIO_PIN_SET);
        HAL_Delay(1);
        HAL_GPIO_WritePin(GPIOB, GPIO_PIN_10, GPIO_PIN_RESET);
        HAL_Delay(1);
    }

    // 4. Generate a STOP condition manually
    HAL_GPIO_WritePin(GPIOB, GPIO_PIN_11, GPIO_PIN_RESET); // SDA low
    HAL_Delay(1);
    HAL_GPIO_WritePin(GPIOB, GPIO_PIN_10, GPIO_PIN_SET);   // SCL high
    HAL_Delay(1);
    HAL_GPIO_WritePin(GPIOB, GPIO_PIN_11, GPIO_PIN_SET);   // SDA high

    // 5. Re-init I2C peripheral
    MX_I2C2_Init();
}

void icm20948_init(void)
{
    uint8_t data;
    uint8_t who_am_i;

    I2C_Bus_Recovery();

    // Select bank 0 (just to be safe)
	data = 0x00;
	HAL_I2C_Mem_Write(&hi2c2, 0x68 << 1, 0x7F, I2C_MEMADD_SIZE_8BIT, &data, 1, 1000);

	// Read WHO_AM_I (0x00) - should be 0xEA
	HAL_I2C_Mem_Read(&hi2c2, 0x68 << 1, 0x00, I2C_MEMADD_SIZE_8BIT, &who_am_i, 1, 1000);
	if (HAL_I2C_Mem_Read(&hi2c2, 0x68<<1, 0x00, I2C_MEMADD_SIZE_8BIT, &who_am_i, 1, 1000) == HAL_OK) {
	    if (who_am_i == 0xEA) {
	        OLED_ShowString(95,35,"ok");
	    } else {
	        OLED_ShowString(95,35,"bad");
	    }
	} else {
	    OLED_ShowString(95,35,"i2c");
	}

    // Wake up
    data = 0x01;
    HAL_I2C_Mem_Write(&hi2c2, 0x68 << 1, 0x06, I2C_MEMADD_SIZE_8BIT, &data, 1, 1000);

    // Enable accel & gyro
    data = 0x00;
    HAL_I2C_Mem_Write(&hi2c2, 0x68 << 1, 0x07, I2C_MEMADD_SIZE_8BIT, &data, 1, 1000);

    // Disable ICM internal I2C master (required for BYPASS)
	data = 0x00; // USER_CTRL (0x03)
	HAL_I2C_Mem_Write(&hi2c2, 0x68<<1, 0x03, I2C_MEMADD_SIZE_8BIT, &data, 1, 1000);

	// Enable BYPASS so MCU can talk to AK09916 at 0x0C
	data = 0x02; // INT_PIN_CFG (0x0F): BYPASS_EN=1
	HAL_I2C_Mem_Write(&hi2c2, 0x68<<1, 0x0F, I2C_MEMADD_SIZE_8BIT, &data, 1, 1000);

	// Put AK09916 into continuous mode (e.g., 100 Hz)
	data = 0x08; // CNTL2 (0x31): 100 Hz
	HAL_I2C_Mem_Write(&hi2c2, 0x0C<<1, 0x31, I2C_MEMADD_SIZE_8BIT, &data, 1, 1000);
}

void PID_Compute(PID_Controller *pid, float error, float dt)
{
	// Integral term with anti-windup
	pid->integral += error * dt;
	if (pid->integral > INTEGRAL_MAX_MOTOR) pid->integral = INTEGRAL_MAX_MOTOR;
	if (pid->integral < -INTEGRAL_MAX_MOTOR) pid->integral = -INTEGRAL_MAX_MOTOR;

	// Derivative term
	float derivative = (error - pid->prevError) / dt;

	// PID output
	float output = pid->Kp * error
				 + pid->Ki * pid->integral
				 + pid->Kd * derivative;

	// Clamp to output range
	if (output > OUTPUT_MAX_MOTOR) output = OUTPUT_MAX_MOTOR;
	if (output < OUTPUT_MIN_MOTOR) output = OUTPUT_MIN_MOTOR;

	pid->pid_change = output;
	pid->prevError = error;
	pid->pwm_output += (int)output;
	if (pid->pwm_output > OUTPUT_MAX_MOTOR) pid->pwm_output = OUTPUT_MAX_MOTOR;
	if (pid->pwm_output < 0) pid->pwm_output = 0;

}

void forward(float target_rpm, float target_distance, int delay, int flag){
	//-------------------- MOTOR START -----------------------
	setPID(&pid_left, 1.5f, 0.0f, 0.0f, 0);
	setPID(&pid_right, 1.5f, 0.0f, 0.0f, 0);
	MotorDrive_enable();
	Motor_direction_both(1);
	//--------------------------------------------------------

	distance_travelled = 0.0f;
	total_left_encoder = 0.0f;

	//-------------- Front tire correction ------------------
	if (servo_prev != SERVO_LEFT){
		rotate_wheel(SERVO_LEFT+10);
		osDelay(100);
		rotate_wheel(SERVO_MIDDLE);
		osDelay(100);
		servo_prev = SERVO_LEFT;
	}
	//-------------------------------------------------------

	for (;;){
		if (emergency_stop){
			MotorStop_both();
			break;
		}

		//--------------- PID Controller -------------------------
		  error_left_rpm = (target_rpm) - motor_left_rpm;
		  error_right_rpm = (target_rpm + RPM_OFFSET) - motor_right_rpm;

		  PID_Compute(&pid_left, error_left_rpm, (float)(delay/1000.0f));
		  PID_Compute(&pid_right, error_right_rpm, (float)(delay/1000.0f));

		  __HAL_TIM_SetCompare(&htim9,TIM_CHANNEL_2,pid_left.pwm_output);  //Motor B (left)
		  __HAL_TIM_SetCompare(&htim4,TIM_CHANNEL_4,pid_right.pwm_output); //Motor A (right)
		//-------------------------------------------------------------

		//-------------- Distance Calculation ----------------------
		  total_revolution = total_left_encoder / 1525.0f;  //1320 OR 1405
		  distance_travelled = total_revolution * 20.41f;  // wheel circumference = 20.736 OR 20.41,

		  total_revolution_int = total_revolution;
		  distance_travelled_int = distance_travelled;
		//-----------------------------------------------------------

		//flag = 1 is used to indicate that the function was called to stop the robot
		//-------------------- Check distance travelled ------------------
		  if (distance_travelled >= target_distance){
			  if (flag){
				  reverse(40.0f, 1.0f, 40, 1);
			  }
			  else{
				  MotorStop_both();
			  }
			  break;
		  }
		//-----------------------------------------------------------------

		  osDelay(delay);
	}
}

void forward_until(float target_rpm, float target_distance, int delay, int flag){
	//-------------------- MOTOR START -----------------------
	setPID(&pid_left, 1.5f, 0.0f, 0.0f, 0);
	setPID(&pid_right, 1.5f, 0.0f, 0.0f, 0);
	MotorDrive_enable();
	Motor_direction_both(1);
	//--------------------------------------------------------

	distance_travelled = 0.0f;
	total_left_encoder = 0.0f;

	//-------------- Front tire correction ------------------
	if (servo_prev != SERVO_LEFT){
		rotate_wheel(SERVO_LEFT);
		osDelay(100);
		rotate_wheel(SERVO_MIDDLE);
		osDelay(100);
		servo_prev = SERVO_LEFT;
	}
	//-------------------------------------------------------

	for (;;){
		if (emergency_stop){
			MotorStop_both();
			break;
		}
		//--------------- PID Controller -------------------------
		error_left_rpm = (target_rpm) - motor_left_rpm;
		error_right_rpm = (target_rpm + RPM_OFFSET) - motor_right_rpm;

		  PID_Compute(&pid_left, error_left_rpm, (float)(delay/1000.0f));
		  PID_Compute(&pid_right, error_right_rpm, (float)(delay/1000.0f));

		  __HAL_TIM_SetCompare(&htim9,TIM_CHANNEL_2,pid_left.pwm_output);  //Motor B (left)
		  __HAL_TIM_SetCompare(&htim4,TIM_CHANNEL_4,pid_right.pwm_output); //Motor A (right)
		//-------------------------------------------------------------

		//-------------- Distance Calculation ----------------------
		  total_revolution = total_left_encoder / 1525.0f;  //1320 OR 1405
		  distance_travelled = total_revolution * 20.41f;  // wheel circumference = 20.736 OR 20.41,

		  total_revolution_int = total_revolution;
		  distance_travelled_int = distance_travelled;
		//----------- End of Distance Calculation ------------------

		//-------------------- Check distance travelled ------------------
		  if (us_dist <= target_distance){
			  if (flag){
				  reverse(40.0f, 1.0f, 40, 1);
			  }
			  else{
				  MotorStop_both();
			  }
			  break;
		  }
		//-----------------------------------------------------------------

		  osDelay(delay);
	}
}

void reverse(float target_rpm, float target_distance, int delay, int flag){
	//-------------------- MOTOR START -----------------------
	setPID(&pid_left, 1.5f, 0.0f, 0.0f, 0);
	setPID(&pid_right, 1.5f, 0.0f, 0.0f, 0);
	MotorDrive_enable();
	Motor_direction_both(0);
	//--------------------------------------------------------

	distance_travelled = 0.0f;
	total_left_encoder = 0;

	//-------------- Front tire correction ------------------
	if (servo_prev != SERVO_LEFT){
		rotate_wheel(SERVO_LEFT);
		osDelay(100);
		rotate_wheel(SERVO_MIDDLE);
		osDelay(100);
		servo_prev = SERVO_LEFT;
	}
	//-------------------------------------------------------

	for (;;){
		if (emergency_stop){
			MotorStop_both();
			break;
		}
		//--------------- PID Controller -------------------------
		error_left_rpm = (target_rpm) - motor_left_rpm;
		error_right_rpm = (target_rpm + RPM_BACK_OFFSET) - motor_right_rpm;

		  PID_Compute(&pid_left, error_left_rpm, (float)(delay/1000.0f));
		  PID_Compute(&pid_right, error_right_rpm, (float)(delay/1000.0f));

		  __HAL_TIM_SetCompare(&htim9,TIM_CHANNEL_1,pid_left.pwm_output);  //Motor B (left)
		  __HAL_TIM_SetCompare(&htim4,TIM_CHANNEL_3,pid_right.pwm_output); //Motor A (right)
		//-------------------------------------------------------------

		//-------------- Distance Calculation ----------------------
		  total_revolution = total_left_encoder / 1525.0f;  //1320 OR 1405
		  distance_travelled = total_revolution * 20.41f;  // wheel circumference = 20.736 OR 20.41,

		  total_revolution_int = total_revolution;
		  distance_travelled_int = distance_travelled;
		//----------------------------------------------------------

		//-------------------- Check distance travelled ------------------
		  if (distance_travelled >= target_distance){
			  if (flag){
				  forward(40.0f, 1.0f, 40, 1);
			  }
			  else{
				  MotorStop_both();
			  }
			  break;
		  }
		//-----------------------------------------------------------------

		  osDelay(delay);
	}
}

void reverse_until(float target_rpm, float target_distance, int delay, int flag){
	//-------------------- MOTOR START -----------------------
	setPID(&pid_left, 1.5f, 0.0f, 0.0f, 0);
	setPID(&pid_right, 1.5f, 0.0f, 0.0f, 0);
	MotorDrive_enable();
	Motor_direction_both(0);
	//--------------------------------------------------------

	distance_travelled = 0.0f;
	total_left_encoder = 0;

	//-------------- Front tire correction ------------------
	if (servo_prev != SERVO_LEFT){
		rotate_wheel(SERVO_LEFT);
		osDelay(100);
		rotate_wheel(SERVO_MIDDLE);
		osDelay(100);
		servo_prev = SERVO_LEFT;
	}
	//-------------------------------------------------------

	for (;;){
		if (emergency_stop){
			MotorStop_both();
			break;
		}
		//--------------- PID Controller -------------------------
		error_left_rpm = (target_rpm) - motor_left_rpm;
		error_right_rpm = (target_rpm + RPM_BACK_OFFSET) - motor_right_rpm;

		  PID_Compute(&pid_left, error_left_rpm, (float)(delay/1000.0f));
		  PID_Compute(&pid_right, error_right_rpm, (float)(delay/1000.0f));

		  __HAL_TIM_SetCompare(&htim9,TIM_CHANNEL_1,pid_left.pwm_output);  //Motor B (left)
		  __HAL_TIM_SetCompare(&htim4,TIM_CHANNEL_3,pid_right.pwm_output); //Motor A (right)
		//-------------------------------------------------------------

		//-------------- Distance Calculation ----------------------
		  total_revolution = total_left_encoder / 1525.0f;  //1320 OR 1405
		  distance_travelled = total_revolution * 20.41f;  // wheel circumference = 20.736 OR 20.41,

		  total_revolution_int = total_revolution;
		  distance_travelled_int = distance_travelled;
		//----------------------------------------------------------

		//-------------------- Check distance travelled ------------------
		  if (us_dist >= target_distance){
			  if (flag){
				  forward(40.0f, 1.0f, 40, 1);
			  }
			  else{
				  MotorStop_both();
			  }
			  break;
		  }
		//-----------------------------------------------------------------

		  osDelay(delay);
	}
}

void forwardTurn(int dir, float target_angle, float target_rpm, int delay){
	//-------------------- Servo Init -----------------------
	HAL_TIM_PWM_Start(&htim12, TIM_CHANNEL_1);
	htim12.Instance->CCR1 = dir;
	if (dir < SERVO_MIDDLE){
		servo_prev = SERVO_LEFT;
	}
	else{
		servo_prev = SERVO_RIGHT;
	}
	//--------------------------------------------------------

	//-------------------- MOTOR START -----------------------
	setPID(&pid_left, 1.0f, 0.0f, 0.0f, 0);
	setPID(&pid_right, 1.0f, 0.0f, 0.0f, 0);
	MotorDrive_enable();
	Motor_direction_both(1);
	//--------------------------------------------------------

	osDelay(100);
	prev_angle_direction = 0.0f;
	angle_direction = 0.0f;

	for (;;){
		if (emergency_stop){
			MotorStop_both();
			break;
		}
		//------------- Turning motion -------------------------
		  error_angle = target_angle - fabsf(angle_direction);
		  error_angle_int = error_angle;
		//------------------------------------------------------

		//--------------- PID Controller -------------------------
		  if (dir > SERVO_MIDDLE){
			  error_left_rpm = (target_rpm) - motor_left_rpm;          //60rpm
			  error_right_rpm = (target_rpm-15.0f) - motor_right_rpm;  //40rpm
		  }
		  else{
			  error_left_rpm = (target_rpm-15.0f) - motor_left_rpm;
			  error_right_rpm = (target_rpm) - motor_right_rpm;
		  }

		  PID_Compute(&pid_left, error_left_rpm, (float)(delay/1000.0f));
		  PID_Compute(&pid_right, error_right_rpm, (float)(delay/1000.0f));

		  __HAL_TIM_SetCompare(&htim9,TIM_CHANNEL_2,pid_left.pwm_output);  //Motor B (left)
		  __HAL_TIM_SetCompare(&htim4,TIM_CHANNEL_4,pid_right.pwm_output); //Motor A (right)
		//-------------------------------------------------------------

		//------------------ Check angle turned --------------------------
		  if ((error_angle) <= 0.0f){
			  MotorStop_both();
			  osDelay(300);
			  htim12.Instance->CCR1 = SERVO_MIDDLE;
			  break;
		  }
		//----------------------------------------------------------------

		  osDelay(delay);
	}

}

void reverseTurn(int dir, float target_angle, float target_rpm, int delay){
	//-------------------- Servo Init -----------------------
	HAL_TIM_PWM_Start(&htim12, TIM_CHANNEL_1);
	htim12.Instance->CCR1 = dir;
	if (dir < SERVO_MIDDLE){
		servo_prev = SERVO_LEFT;
	}
	else{
		servo_prev = SERVO_RIGHT;
	}
	//--------------------------------------------------------

	//-------------------- MOTOR START -----------------------
	setPID(&pid_left, 1.0f, 0.0f, 0.0f, 0);
	setPID(&pid_right, 1.0f, 0.0f, 0.0f, 0);
	MotorDrive_enable();
	Motor_direction_both(0);
	//--------------------------------------------------------

	osDelay(100);
	prev_angle_direction = 0.0f;
	angle_direction = 0.0f;

	for (;;){
		if (emergency_stop){
			MotorStop_both();
			break;
		}
		//------------- Turning motion -------------------------
		  error_angle = target_angle - fabsf(angle_direction);
		  error_angle_int = error_angle;
		//------------------------------------------------------

		//--------------- PID Controller -------------------------
		  if (dir > SERVO_MIDDLE){
			  error_left_rpm = (target_rpm) - motor_left_rpm;          //60rpm
			  error_right_rpm = (target_rpm-15.0f) - motor_right_rpm;  //40rpm
		  }
		  else{
			  error_left_rpm = (target_rpm-15.0f) - motor_left_rpm;
			  error_right_rpm = (target_rpm) - motor_right_rpm;
		  }

		  PID_Compute(&pid_left, error_left_rpm, (float)(delay/1000.0f));
		  PID_Compute(&pid_right, error_right_rpm, (float)(delay/1000.0f));

		  __HAL_TIM_SetCompare(&htim9,TIM_CHANNEL_1,pid_left.pwm_output);  //Motor B (left)
		  __HAL_TIM_SetCompare(&htim4,TIM_CHANNEL_3,pid_right.pwm_output); //Motor A (right)
		//-------------------------------------------------------------

		//------------------ Check angle turned --------------------------
		  if ((error_angle) <= 0.0f){
			  MotorStop_both();
			  osDelay(300);
			  htim12.Instance->CCR1 = SERVO_MIDDLE;
			  break;
		  }
		//----------------------------------------------------------------

		  osDelay(delay);
	}

}

void buzzerOn(int delay){
	HAL_GPIO_TogglePin(GPIOA, GPIO_PIN_8);
	osDelay(delay);
	HAL_GPIO_TogglePin(GPIOA, GPIO_PIN_8);
}

void rotate_wheel(int side){
	HAL_TIM_PWM_Start(&htim12, TIM_CHANNEL_1);
	htim12.Instance->CCR1 = side;
}

//115 - 30deg
//102 - 25
//95 - 20
//90 ~ 15
//86 - 10
//76 - 0
//67 - 10
//63 - 15
//60 - 20
//55 ~ 25
//53 - 30
void convert_from_angle(int angle){
	switch (angle){
		case 30:
			servo_curr = 115;
			break;
		case 25:
			servo_curr = 102;
			break;
		case 20:
			servo_curr = 95;
			break;
		case 15:
			servo_curr = 90;
			break;
		case 10:
			servo_curr = 86;
			break;
		case 0:
			servo_curr = 76;
			break;
		case -10:
			servo_curr = 67;
			break;
		case -15:
			servo_curr = 63;
			break;
		case -20:
			servo_curr = 60;
			break;
		case -25:
			servo_curr = 55;
			break;
		case -30:
			servo_curr = 53;
			break;
	}
}

/* USER CODE END 4 */

void StartDefaultTask(void *argument)
{
  /* USER CODE BEGIN 5 */

  /* Infinite loop */
  for(;;)
  {

	// Toggle LED every 1s to show that STM not stuck in loop and still running
	HAL_GPIO_TogglePin(LED3_GPIO_Port, LED3_Pin);
	osDelay(1000);

  }
  /* USER CODE END 5 */
}

void show(void *argument)
{
  /* USER CODE BEGIN show */
	char buffer[20];

  /* Infinite loop */
  for(;;)
  {
	  sprintf(buffer, "Motor L:%2d R:%2d", motor_left_rpm_int, motor_right_rpm_int);
	  OLED_ShowString(5, 5, buffer);

	  sprintf(buffer, "Dist:%4d", distance_travelled_int);
	  OLED_ShowString(5, 15, buffer);

	  sprintf(buffer, "IR L:%2d R:%2d", ir_dist_left_int, ir_dist_right_int);
	  OLED_ShowString(5, 25, buffer);

	  sprintf(buffer, "US:%3d", us_dist_int);
	  OLED_ShowString(5, 35, buffer);

//	  sprintf(buffer, "Angle:%3d", gyro_z_dps_int);
//	  sprintf(buffer, "%04d-\0", pid_right.pwm_output);
//	  sprintf(buffer, "%04d--", encoder_difference);
//	  OLED_ShowString(5, 45, buffer);

	// Refreshes the OLED screen every 0.5s
	// This is the only refresh function call in all the tasks
	OLED_Refresh_Gram();

    osDelay(250);
  }
  /* USER CODE END show */
}

void motors(void *argument)
{
  /* USER CODE BEGIN motors */

	int flag = 0;
	int count = 0;
	int image_check;
	int start = 0;

	//---------- Starting ----------
	//start only when user button pressed
	osDelay(2000);//delay for ultrasonic init
	rotate_wheel(SERVO_LEFT+10);
	osDelay(500);
	rotate_wheel(SERVO_MIDDLE);
	osDelay(500);
//	rotate_wheel(SERVO_MIDDLE);
//	for (;;){
//		osDelay(10);
//		if (HAL_GPIO_ReadPin(GPIOE, GPIO_PIN_0) == RESET){
//			break;
//		}
//	}
//	forward_until(100.0f, 15.0f, 40, 0);
	//-------------------------------

	//---------- Testing --------------
	//currently, diameter = 63~65
//	forwardTurn(LEFT, 180.0f, 60.0f, 40);

//	reverse(100.0f, 100.0f, 40, 0);
	//---------------------------------
//    osDelay(1000);
//    rotate_wheel(63);

  /* Infinite loop */
  for(;;)
  {

	  //***** Un-comment to stop *****
//	  osDelay(1000);
//	  continue;
	  //*****************************

	  //------------- Checklist (Movement around object) ------------------------
	  if (flag){
		  osDelay(1000);
		  continue;
	  }
//
//	  osDelay(1000); //Time delay to recognise image
//
//	  reverse(60.0f, 20.0f, 40, 0);
//	  osDelay(300);
//
//	  forwardTurn(LEFT, 45.0f, 60.0f, 40);
//	  osDelay(300);
//	  forwardTurn(RIGHT, 45.0f, 60.0f, 40);
//	  osDelay(300);
//
//	  forward(100.0f, 36.0f, 40, 0);
//	  osDelay(500);
//	  reverseTurn(LEFT, 88.0f, 60.0f, 40);
//	  osDelay(300);
//
//	  forward_until(60.0f, 15.0f, 40, 0);
//	  osDelay(1000);
//
//	  count++;
//	  if (count == 3){
//		  flag = 1;
//		  osDelay(200);
//	  }
	  //-------------------------------------------------------------------------

	  //---------------- Receiving Instruction from RPi ----------------------
      // Add emergency stop check at the TOP of the loop
      if (emergency_stop) {
          MotorStop_both();
          osDelay(100);
          continue;  // Skip rest of iteration
      }

	  osDelay(10);
	  if (!have_instruction){
		  MotorStop_both();
		  continue;
	  }
		//T - forward
		//W - forward_until
		//t - reverse
		//w - reverse_until
	    //{flag}{speed}|{angle}|{value}
	  else{
		  if (instruction[0] == 'S'){
			  buzzerOn(500);
			  osDelay(2000);
		  }

		  else if (instruction[0] == 'F'){
			  buzzerOn(2000);
			  flag = 1;
		  }

		  else{
			  convert_instruction(&instruction);
			  if (i_angle == 0){  //forward or backward
				  switch (i_flag){
					  case 'T':
						  forward(i_speed+10, i_value, 40, 0);
						  break;
					  case 't':
						  reverse(i_speed+10, i_value, 40, 0);
						  break;
					  case 'W':
						  forward_until(i_speed+10, i_value, 40, 0);
						  break;
					  case 'w':
						  reverse_until(i_speed+10, i_value, 40, 0);
						  break;
				  }
			  }

			  else if (i_angle > 0){ //turn right
				  if (i_angle > 30) i_angle = 30;
				  convert_from_angle(i_angle);
				  if (i_flag == 'T') {
					  forwardTurn(servo_curr, i_value, 50.0f, 40);
				  }
				  else{
					  reverseTurn(servo_curr, i_value, 50.0f, 40);
				  }
			  }

			  else{ //turn left
				  if (i_angle < -30) i_angle = -30;
				  convert_from_angle(i_angle);
				  sprintf(buffer, "%3d", servo_curr);
				  OLED_ShowString(70, 35, buffer);
				  if (i_flag == 'T'){
					  forwardTurn(servo_curr, i_value, 50.0f, 40);
				  }
				  else{
					  reverseTurn(servo_curr, i_value, 50.0f, 40);
				  }
			  }
		  }

//		  sprintf(buffer, "%c,%d,%d,%d,FIN\r\n", i_flag, (int)i_speed, (int)i_angle, (int)i_value);
		  sprintf(buffer, "FIN\r\n");
		  HAL_UART_Transmit(&huart3, buffer, strlen(buffer), 0xFFFF);
		  have_instruction = 0;
	  }
	  //----------------------------------------------------------------------

  }
  /* USER CODE END motors */
}

void encoder(void *argument)
{
  /* USER CODE BEGIN encoder */
  /* Infinite loop */
  // --------------- Right Motor (Motor A) --------------------------
  HAL_TIM_PWM_Start(&htim2, TIM_CHANNEL_2);
  HAL_TIM_PWM_Start(&htim2, TIM_CHANNEL_1);

  int cnt1A, cnt2A;
  uint32_t tickA;

  cnt1A = __HAL_TIM_GET_COUNTER(&htim2);
  tickA = HAL_GetTick();
  uint8_t display1[20];
  uint8_t display2[20];
  uint16_t dirA;
  float a = 0.95f;

  for(;;)
  {
    if (HAL_GetTick() - tickA > 40L){
    	cnt2A = __HAL_TIM_GET_COUNTER(&htim2);
    	if (__HAL_TIM_IS_TIM_COUNTING_DOWN(&htim2)){
    		if (cnt2A < cnt1A)
    			motor_right_encoder = cnt1A - cnt2A;
    		else
    			motor_right_encoder = (65535 - cnt2A) + cnt1A;
    	}
    	else{
    		if (cnt2A > cnt1A)
    			motor_right_encoder = cnt2A - cnt1A;
    		else
    			motor_right_encoder = (65535 - cnt1A) + cnt2A;
    	}

    	//------------------------------- with LPF ---------------------------------------
    	if (motor_right_encoder > 250){
    		motor_right_encoder = 0;
    		motor_right_encoder_lpf = 0;
    	}
    	total_right_encoder += motor_right_encoder;
    	motor_right_encoder *= 25;
    	motor_right_rpm = motor_right_encoder / 22.0f; // 60/1320 = 1/22

    	motor_right_encoder_lpf = (motor_right_encoder * (1-a)) + (prev_right_encoder * a);
    	prev_right_encoder = motor_right_encoder_lpf;  // for LPF
    	motor_right_rpm_lpf = motor_right_encoder_lpf / 22.0f; // 60/1320 = 1/22
    	motor_right_rpm_lpf_int = motor_right_rpm_lpf;
    	//---------------------------------------------------------------------------------

    	motor_right_rpm_int = motor_right_rpm;
    	dirA = __HAL_TIM_IS_TIM_COUNTING_DOWN(&htim2);

    	//---------- Reset Procedure ------------
    	cnt1A = __HAL_TIM_GET_COUNTER(&htim2);
	    tickA = HAL_GetTick();
	    //---------------------------------------
    }
  }
  /* USER CODE END encoder */
}

void encoder_B(void *argument)
{
  /* USER CODE BEGIN encoder_B */
	// --------------- Left Motor (Motor B) --------------------------
	HAL_TIM_PWM_Start(&htim3, TIM_CHANNEL_2);
	HAL_TIM_PWM_Start(&htim3, TIM_CHANNEL_1);

	int cnt1A, cnt2A;
	uint32_t tickA;

	cnt1A = __HAL_TIM_GET_COUNTER(&htim3);
	tickA = HAL_GetTick();
	uint8_t display1[20];
	uint8_t display2[20];
	uint16_t dirA;
	float a = 0.95f;

	char sbuf[64];

	for(;;)
	{
	if (HAL_GetTick() - tickA > 40L){
		cnt2A = __HAL_TIM_GET_COUNTER(&htim3);
		if (__HAL_TIM_IS_TIM_COUNTING_DOWN(&htim3)){
			if (cnt2A < cnt1A)
				motor_left_encoder = cnt1A - cnt2A;
			else
				motor_left_encoder = (65535 - cnt2A) + cnt1A;
		}
		else{
			if (cnt2A > cnt1A)
				motor_left_encoder = cnt2A - cnt1A;
			else
				motor_left_encoder = (65535 - cnt1A) + cnt2A;
		}

		//---------------------- with LPF --------------------------
		if (motor_left_encoder > 250){
			motor_left_encoder = 0;
			motor_left_encoder_lpf = 0;
		}
		total_left_encoder += motor_left_encoder;
		motor_left_encoder *= 25;
		motor_left_rpm = motor_left_encoder / 22.0f;  //  60/1320 = 1/22

		motor_left_encoder_lpf = (motor_left_encoder * (1-a)) + (prev_left_encoder * a);  //for LPF
		prev_left_encoder = motor_left_encoder_lpf;  //for LPF
		motor_left_rpm_lpf = motor_left_encoder_lpf / 22.0f;  //  60/1320 = 1/22
		motor_left_rpm_lpf_int = motor_left_rpm_lpf;
		//-----------------------------------------------------------

		motor_left_rpm_int = motor_left_rpm;
		dirA = __HAL_TIM_IS_TIM_COUNTING_DOWN(&htim3);
		dirA = !(dirA);

		//------------ Reset Procedure -------------
		cnt1A = __HAL_TIM_GET_COUNTER(&htim3);
		tickA = HAL_GetTick();
		//------------------------------------------

		}
	}
  /* USER CODE END encoder_B */
}

void ultra_sensor(void *argument)
{
  /* USER CODE BEGIN ultra_sensor */
	char buf[20];
  /* Infinite loop */
  for(;;)
  {
	  HAL_GPIO_WritePin(TRIG_Port, TRIG_Pin, GPIO_PIN_RESET);
	  osDelay(50);

	  //Output 1us of Trig
	  HAL_GPIO_WritePin(TRIG_Port, TRIG_Pin, GPIO_PIN_SET);
	  delay_us(10);
	  HAL_GPIO_WritePin(TRIG_Port, TRIG_Pin, GPIO_PIN_RESET);
	  osDelay(50);

	  //wait for rising edge
	  HAL_TIM_IC_Start_IT(&htim8, TIM_CHANNEL_2);
	  HAL_TIM_IC_CaptureCallback(&htim8);

	  us_dist = us_echo * 0.01715;
	  if (us_dist > 400.0f) us_dist = 400.0f;
	  if (us_dist < 0.0f) us_dist = 0.0f;
	  us_dist_int = us_dist;

  }
  /* USER CODE END ultra_sensor */
}

void sensor_reading(void *argument)
{
  /* USER CODE BEGIN sensor_reading */
	uint8_t reg_addr = 0x37;    // start from GYRO_ZOUT_H
	uint8_t rawData[2];         // to store MSB and LSB
	float B = 0.9f;

	int16_t drift_raw, drift_total=0;
	float drift_degrees;

	int delay = 10;
	float dt;
	double offset = 0;
	double trash = 0;
	int i = 0;
	uint32_t tick1, tick2;

	icm20948_init();
	osDelay(100); //delay to make sure ICM 20948 power up

	tick1 = HAL_GetTick();

	while (i < 1000){
		osDelay(1);
		HAL_I2C_Master_Transmit(&hi2c2, 0x68 << 1, &reg_addr, 1, 1000);
		HAL_I2C_Master_Receive(&hi2c2, 0x68 << 1, rawData, 2, 1000);
		drift_raw = (int16_t)((rawData[0] << 8) | rawData[1]);
		offset += drift_raw;
		tick1 = HAL_GetTick();
		i++;
	}
	offset = offset/i;

	tick1 = HAL_GetTick();
  /* Infinite loop */
  for(;;)
  {
	//------------------- Gyroscope Readings ---------------------------------------
	// Step 1: Tell sensor which register to read
	if(HAL_I2C_Master_Transmit(&hi2c2, 0x68 << 1, &reg_addr, 1, 1000)!= HAL_OK){
		OLED_ShowString(5, 5, "0");
	}

	// Step 2: Read 2 bytes (MSB + LSB)
	if (HAL_I2C_Master_Receive(&hi2c2, 0x68 << 1, rawData, 2, 1000)!=HAL_OK){
		OLED_ShowString(5, 5, "1");
	}
	// Combine into signed 16-bit value
	gyro_z_raw = (int16_t)((rawData[0] << 8) | rawData[1]);
	gyro_z_raw -= offset;
	gyro_z_dps = gyro_z_raw / 131.0f;
	gyro_z_dps_int = gyro_z_dps;
	// -----------------------------------------------------------------------------

	//-------------------- Angle Calculation -----------------------
	tick2 = HAL_GetTick();
	dt = (tick2-tick1) / 1000.0f;
	angle_direction = prev_angle_direction + (gyro_z_dps * dt);
	prev_angle_direction = angle_direction;
	angle_direction_int = angle_direction;
	//--------------------------------------------------------------

	tick1 = tick2;

	osDelay(1);
  }
  /* USER CODE END sensor_reading */
}

void ir_dist(void *argument)
{
  /* USER CODE BEGIN ir_dist */

  /* Infinite loop */
  for(;;)
  {
	// ---------------- IR Sensor Left Readings ------------------------
	HAL_ADC_Start(&hadc1);
	HAL_ADC_PollForConversion(&hadc1, 20);
	ir_raw_left = HAL_ADC_GetValue(&hadc1);
	HAL_ADC_Stop(&hadc1);

	//  40483.4058f / (raw + 50.8020f) - 4.6692f;
	ir_dist_left = (40483.4058f / (ir_raw_left + 50.8020f)) - 4.6692f;
	if (ir_dist_left > 40.0f) ir_dist_left = 40.0;
	if (ir_dist_left < 0.0f) ir_dist_left = 0.0f;
	ir_dist_left_int = ir_dist_left;
	// -------------------------------------------------------------------

	// ------------------ IR Sensor Right Readings  -----------------------
	HAL_ADC_Start(&hadc2);
	HAL_ADC_PollForConversion(&hadc2, 20);
	ir_raw_right = HAL_ADC_GetValue(&hadc2);
	HAL_ADC_Stop(&hadc2);

	// 44430.9618f / (raw + 109.84988f) - 5.72134f;
	ir_dist_right = (44430.9618f / (ir_raw_right + 109.84988f)) - 5.72134f;
	if (ir_dist_right > 40.0f) ir_dist_right = 40.0;
 	if (ir_dist_right < 0.0f) ir_dist_right = 0.0f;
	ir_dist_right_int = ir_dist_right;
	//---------------------------------------------------------------------

    osDelay(200);
  }
  /* USER CODE END ir_dist */
}

void transmit(void *argument)
{
  /* USER CODE BEGIN transmit */
  char sbuf[64];
  int target_rpm = 60;

  /* Infinite loop */
  for(;;)
  {

	  //--------------------------------------------- Motor ------------------------------------------
//	  sprintf(sbuf, "%2d,%2d,%3d,%3d,%2d,%7d,0\r\n", motor_left_rpm_int, motor_right_rpm_int,
//			  	  	  	  	  	  	  	  	  motor_left_rpm_lpf_int, motor_right_rpm_lpf_int, target_rpm,
//											  encoder_difference);

//	  sprintf(sbuf, "%5d,100\r\n", distance_travelled_int);

//	  sprintf(sbuf, "%2d,%2d,%3d,%3d,%2d,%4d,%4d,0\r\n", motor_left_rpm_int, motor_right_rpm_int,
//			  	  	  	  	  	  	  	  	  (int)error_left_rpm, (int)error_right_rpm, target_rpm,
//	  	  	  	  	  	  	  	  	  	  	  pid_left.pwm_output, pid_right.pwm_output);
	  //-----------------------------------------------------------------------------------------------

	  //------------------------------- Turning Motion ----------------------------------------------
//	  sprintf(sbuf, "%2d,%3d\r\n", error_angle, angle_direction_hpf_int);
	  //---------------------------------------------------------------------------------------------

	  //------------------------------ Gyroscope readings -------------------------------------
//	  sprintf(sbuf, "%5d,%3d,%3d,%3d,90\r\n", gyro_z_raw, gyro_z_dps_int, angle_direction_int, error_angle_int);
	  //---------------------------------------------------------------------------------------

	  //----------------------- IR Distance / UART w RPi -------------------------------
//	  sprintf(sbuf, "%02d,%02d,%03d\r\n", ir_dist_left_int, ir_dist_right_int, us_dist_int);
	  //--------------------------------------------------------------------------------

//	  HAL_UART_Transmit(&huart3, sbuf, strlen(sbuf), 0xFFFF);

    osDelay(200);
  }
  /* USER CODE END transmit */
}

void encoder_diff(void *argument)
{
  /* USER CODE BEGIN encoder_diff */
	int left, right;
  /* Infinite loop */
  for(;;)
  {
    left = 65535 - __HAL_TIM_GET_COUNTER(&htim3);
	right = __HAL_TIM_GET_COUNTER(&htim2);
	encoder_difference = left - right;

	osDelay(20);
  }
  /* USER CODE END encoder_diff */
}

void HAL_TIM_PeriodElapsedCallback(TIM_HandleTypeDef *htim)
{
  if (htim->Instance == TIM6)
  {
    HAL_IncTick();
  }
}

void Error_Handler(void)
{
  __disable_irq();
  while (1)
  {
  }
}
